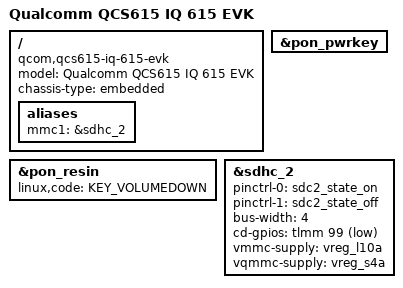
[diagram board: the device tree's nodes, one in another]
// SPDX-License-Identifier: BSD-3-Clause
/*
 * Copyright (c) 2025, Qualcomm Innovation Center, Inc. All rights reserved.
 */
/dts-v1/;

#include "qcs615-som.dtsi"

/ {
	model = "Qualcomm QCS615 IQ 615 EVK";
	compatible = "qcom,qcs615-iq-615-evk", "qcom,qcs615", "qcom,sm6150";
	chassis-type = "embedded";

	aliases {
		mmc1 = &sdhc_2;
	};
};

&pon_pwrkey {
	status = "okay";
};

&pon_resin {
	linux,code = <KEY_VOLUMEDOWN>;

	status = "okay";
};

&sdhc_2 {
	pinctrl-0 = <&sdc2_state_on>;
	pinctrl-1 = <&sdc2_state_off>;
	pinctrl-names = "default", "sleep";

	bus-width = <4>;
	cd-gpios = <&tlmm 99 GPIO_ACTIVE_LOW>;

	vmmc-supply = <&vreg_l10a>;
	vqmmc-supply = <&vreg_s4a>;

	status = "okay";
};
